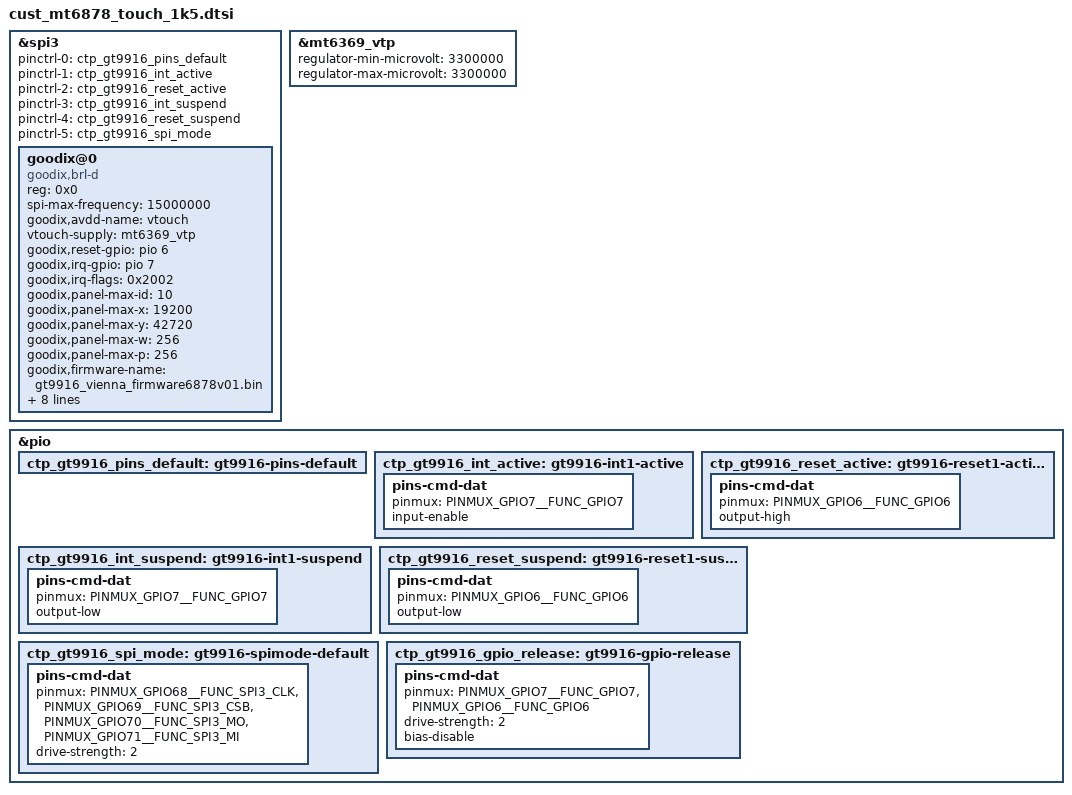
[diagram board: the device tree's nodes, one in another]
// SPDX-License-Identifier: (GPL-2.0 OR MIT)
/*
 * Copyright (C) 2020 MediaTek Inc.
 */

/* TOUCH start */
&spi3 {
	status = "okay";
	#address-cells = <1>;
	#size-cells = <0>;
	pinctrl-names = "default", "gt9916_int_active",
		"gt9916_reset_active", "gt9916_int_suspend",
		"gt9916_reset_suspend", "gt9916_spi_mode";
	pinctrl-0 = <&ctp_gt9916_pins_default>;
	pinctrl-1 = <&ctp_gt9916_int_active>;
	pinctrl-2 = <&ctp_gt9916_reset_active>;
	pinctrl-3 = <&ctp_gt9916_int_suspend>;
	pinctrl-4 = <&ctp_gt9916_reset_suspend>;
	pinctrl-5 = <&ctp_gt9916_spi_mode>;

	goodix@0 {
		status = "ok";
		compatible = "goodix,brl-d";
		reg = <0x0>;
		spi-max-frequency = <15000000>;  /* 4800000,9600000,15000000,19200000 */
		goodix,avdd-name = "vtouch";
		vtouch-supply = <&mt6369_vtp>;
		goodix,reset-gpio = <&pio 6 0x0>;
		goodix,irq-gpio = <&pio 7 0x2002>;
		goodix,irq-flags = <0x2002>; /* 1:rising, 2:falling;*/
		goodix,panel-max-id = <10>;
		goodix,panel-max-x = <19200>;
		goodix,panel-max-y = <42720>;
		goodix,panel-max-w = <256>;
		goodix,panel-max-p = <256>;

		goodix,firmware-name = "gt9916_vienna_firmware6878v01.bin";
		goodix,config-name = "gt9916_vienna_cfg_6878v01.bin";

		pinctrl-names = "default", "sleep", "pmx_ts_release";
		pinctrl-0 = <&ctp_gt9916_pins_default &ctp_gt9916_int_active
				&ctp_gt9916_reset_active &ctp_gt9916_spi_mode>;
		pinctrl-1 = <&ctp_gt9916_int_suspend &ctp_gt9916_reset_suspend>;
		pinctrl-2 = <&ctp_gt9916_gpio_release>;
	};
};
&mt6369_vtp {
	regulator-min-microvolt = <3300000>;
	regulator-max-microvolt = <3300000>;
};
&pio {
	ctp_gt9916_pins_default: gt9916-pins-default {
	};
	ctp_gt9916_int_active: gt9916-int1-active {
		pins-cmd-dat {
			pinmux = <PINMUX_GPIO7__FUNC_GPIO7>;
			input-enable;
		};
	};
	ctp_gt9916_reset_active: gt9916-reset1-active {
		pins-cmd-dat {
			pinmux = <PINMUX_GPIO6__FUNC_GPIO6>;
			output-high;
		};
	};
	ctp_gt9916_int_suspend: gt9916-int1-suspend {
		pins-cmd-dat {
			pinmux = <PINMUX_GPIO7__FUNC_GPIO7>;
			output-low;
		};
	};
	ctp_gt9916_reset_suspend: gt9916-reset1-suspend {
		pins-cmd-dat {
			pinmux = <PINMUX_GPIO6__FUNC_GPIO6>;
			output-low;
		};
	};
	ctp_gt9916_spi_mode: gt9916-spimode-default {
		pins-cmd-dat {
			pinmux = <PINMUX_GPIO68__FUNC_SPI3_CLK>,
				<PINMUX_GPIO69__FUNC_SPI3_CSB>,
				<PINMUX_GPIO70__FUNC_SPI3_MO>,
				<PINMUX_GPIO71__FUNC_SPI3_MI>;
			drive-strength = <2>;
		};
	};
	ctp_gt9916_gpio_release: gt9916-gpio-release {
		pins-cmd-dat {
			pinmux = <PINMUX_GPIO7__FUNC_GPIO7>,
				<PINMUX_GPIO6__FUNC_GPIO6>;
			drive-strength = <2>;
			bias-disable;
		};
	};
};
/* TOUCH end */
